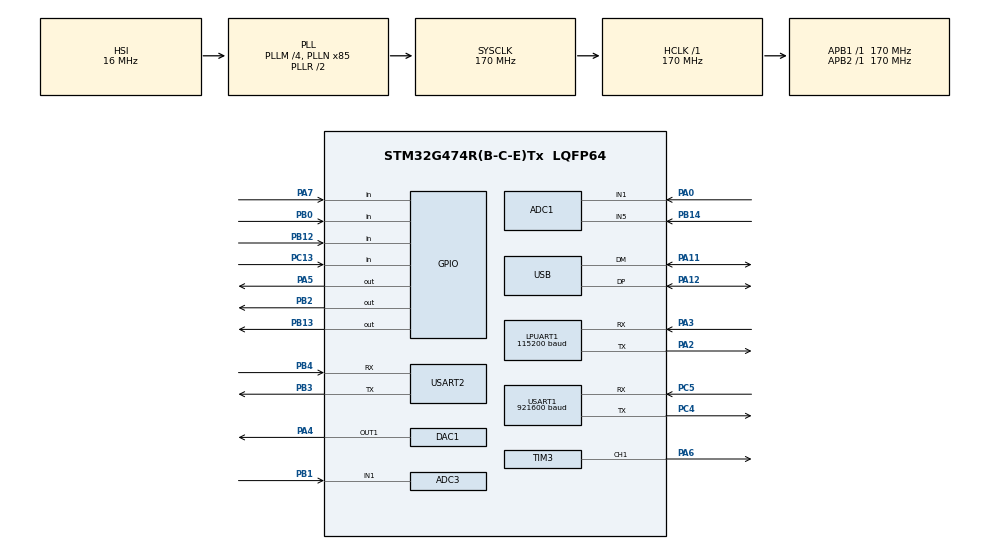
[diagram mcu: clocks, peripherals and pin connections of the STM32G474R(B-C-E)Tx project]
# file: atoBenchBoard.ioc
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ADC1.Channel-0\#ChannelRegularConversion=ADC_CHANNEL_1
ADC1.Channel-1\#ChannelRegularConversion=ADC_CHANNEL_5
ADC1.EOCSelection=ADC_EOC_SEQ_CONV
ADC1.ExternalTrigConv=ADC_EXTERNALTRIG_T7_TRGO
ADC1.NbrOfConversion=2
ADC1.NbrOfConversionFlag=1
ADC1.OffsetNumber-0\#ChannelRegularConversion=ADC_OFFSET_NONE
ADC1.OffsetNumber-1\#ChannelRegularConversion=ADC_OFFSET_NONE
ADC1.Rank-0\#ChannelRegularConversion=1
ADC1.Rank-1\#ChannelRegularConversion=2
ADC1.SamplingTime-0\#ChannelRegularConversion=ADC_SAMPLETIME_47CYCLES_5
ADC1.SamplingTime-1\#ChannelRegularConversion=ADC_SAMPLETIME_47CYCLES_5
ADC1.master=1
ADC3.Channel-0\#ChannelRegularConversion=ADC_CHANNEL_1
ADC3.NbrOfConversionFlag=1
ADC3.OffsetNumber-0\#ChannelRegularConversion=ADC_OFFSET_NONE
ADC3.Rank-0\#ChannelRegularConversion=1
ADC3.SamplingTime-0\#ChannelRegularConversion=ADC_SAMPLETIME_2CYCLES_5
ADC3.master=1
DAC1.DAC_Trigger_OUT1-DAC_OUT1=DAC_TRIGGER_T7_TRGO
Dma.ADC1.2.Direction=DMA_PERIPH_TO_MEMORY
Dma.ADC1.2.EventEnable=DISABLE
Dma.ADC1.2.Instance=DMA1_Channel3
Dma.ADC1.2.MemDataAlignment=DMA_MDATAALIGN_HALFWORD
Dma.ADC1.2.MemInc=DMA_MINC_ENABLE
Dma.ADC1.2.Mode=DMA_NORMAL
Dma.ADC1.2.PeriphDataAlignment=DMA_PDATAALIGN_HALFWORD
Dma.ADC1.2.PeriphInc=DMA_PINC_DISABLE
Dma.ADC1.2.Polarity=HAL_DMAMUX_REQ_GEN_RISING
Dma.ADC1.2.Priority=DMA_PRIORITY_LOW
Dma.ADC1.2.RequestNumber=1
Dma.ADC1.2.SignalID=NONE
Dma.ADC1.2.SyncEnable=DISABLE
Dma.ADC1.2.SyncPolarity=HAL_DMAMUX_SYNC_NO_EVENT
Dma.ADC1.2.SyncRequestNumber=1
Dma.ADC1.2.SyncSignalID=NONE
Dma.DAC1_CH1.3.Direction=DMA_MEMORY_TO_PERIPH
Dma.DAC1_CH1.3.EventEnable=DISABLE
Dma.DAC1_CH1.3.Instance=DMA1_Channel4
Dma.DAC1_CH1.3.MemDataAlignment=DMA_MDATAALIGN_HALFWORD
Dma.DAC1_CH1.3.MemInc=DMA_MINC_ENABLE
Dma.DAC1_CH1.3.Mode=DMA_CIRCULAR
Dma.DAC1_CH1.3.PeriphDataAlignment=DMA_PDATAALIGN_WORD
Dma.DAC1_CH1.3.PeriphInc=DMA_PINC_DISABLE
Dma.DAC1_CH1.3.Polarity=HAL_DMAMUX_REQ_GEN_RISING
Dma.DAC1_CH1.3.Priority=DMA_PRIORITY_LOW
Dma.DAC1_CH1.3.RequestNumber=1
Dma.DAC1_CH1.3.SignalID=NONE
Dma.DAC1_CH1.3.SyncEnable=DISABLE
Dma.DAC1_CH1.3.SyncPolarity=HAL_DMAMUX_SYNC_NO_EVENT
Dma.DAC1_CH1.3.SyncRequestNumber=1
Dma.DAC1_CH1.3.SyncSignalID=NONE
Dma.Request0=USART1_RX
Dma.Request1=USART1_TX
Dma.Request2=ADC1
Dma.Request3=DAC1_CH1
Dma.USART1_RX.0.Direction=DMA_PERIPH_TO_MEMORY
Dma.USART1_RX.0.EventEnable=DISABLE
Dma.USART1_RX.0.Instance=DMA1_Channel1
Dma.USART1_RX.0.MemDataAlignment=DMA_MDATAALIGN_BYTE
Dma.USART1_RX.0.MemInc=DMA_MINC_ENABLE
Dma.USART1_RX.0.Mode=DMA_CIRCULAR
Dma.USART1_RX.0.PeriphDataAlignment=DMA_PDATAALIGN_BYTE
Dma.USART1_RX.0.PeriphInc=DMA_PINC_DISABLE
Dma.USART1_RX.0.Polarity=HAL_DMAMUX_REQ_GEN_RISING
Dma.USART1_RX.0.Priority=DMA_PRIORITY_LOW
Dma.USART1_RX.0.RequestNumber=1
Dma.USART1_RX.0.SignalID=NONE
Dma.USART1_RX.0.SyncEnable=DISABLE
Dma.USART1_RX.0.SyncPolarity=HAL_DMAMUX_SYNC_NO_EVENT
Dma.USART1_RX.0.SyncRequestNumber=1
Dma.USART1_RX.0.SyncSignalID=NONE
Dma.USART1_TX.1.Direction=DMA_MEMORY_TO_PERIPH
Dma.USART1_TX.1.EventEnable=DISABLE
Dma.USART1_TX.1.Instance=DMA1_Channel2
Dma.USART1_TX.1.MemDataAlignment=DMA_MDATAALIGN_BYTE
Dma.USART1_TX.1.MemInc=DMA_MINC_ENABLE
Dma.USART1_TX.1.Mode=DMA_NORMAL
Dma.USART1_TX.1.PeriphDataAlignment=DMA_PDATAALIGN_BYTE
Dma.USART1_TX.1.PeriphInc=DMA_PINC_DISABLE
Dma.USART1_TX.1.Polarity=HAL_DMAMUX_REQ_GEN_RISING
Dma.USART1_TX.1.Priority=DMA_PRIORITY_LOW
Dma.USART1_TX.1.RequestNumber=1
Dma.USART1_TX.1.SignalID=NONE
Dma.USART1_TX.1.SyncEnable=DISABLE
Dma.USART1_TX.1.SyncPolarity=HAL_DMAMUX_SYNC_NO_EVENT
Dma.USART1_TX.1.SyncRequestNumber=1
Dma.USART1_TX.1.SyncSignalID=NONE
FREERTOS.Tasks01=defaultTask,0,128,StartDefaultTask,Default,NULL,Dynamic,NULL,NULL
FREERTOS.configCHECK_FOR_STACK_OVERFLOW=2
FREERTOS.configENABLE_FPU=1
FREERTOS.configTOTAL_HEAP_SIZE=16384
FREERTOS.configUSE_MALLOC_FAILED_HOOK=1
FREERTOS.configUSE_NEWLIB_REENTRANT=1
FREERTOS.configUSE_STATS_FORMATTING_FUNCTIONS=1
FREERTOS.configUSE_TRACE_FACILITY=1
LPUART1.BaudRate=115200
Mcu.Family=STM32G4
Mcu.Name=STM32G474R(B-C-E)Tx
Mcu.Package=LQFP64
NUCLEO-G474RE.BUTTON=2
NUCLEO-G474RE.LD2=false
NUCLEO-G474RE.VCP=false
NVIC.ADC1_2_IRQn=true\:5\:0\:false\:false\:true\:true\:true\:true\:true
NVIC.DMA1_Channel1_IRQn=true\:5\:0\:false\:false\:true\:true\:false\:true\:true
NVIC.DMA1_Channel2_IRQn=true\:5\:0\:false\:false\:true\:true\:false\:true\:true
NVIC.DMA1_Channel3_IRQn=true\:5\:0\:false\:false\:true\:true\:false\:true\:true
NVIC.DMA1_Channel4_IRQn=true\:5\:0\:false\:false\:true\:true\:false\:true\:true
NVIC.PriorityGroup=NVIC_PRIORITYGROUP_4
NVIC.TIM6_DAC_IRQn=true\:5\:0\:false\:false\:true\:false\:false\:true\:true
NVIC.TimeBase=TIM6_DAC_IRQn
NVIC.TimeBaseIP=TIM6
NVIC.USART1_IRQn=true\:5\:0\:false\:false\:true\:true\:true\:true\:true
NVIC.USB_LP_IRQn=true\:5\:0\:false\:false\:false\:true\:true\:true\:false
PA0.Mode=IN1-Single-Ended
PA0.Signal=ADC1_IN1
PA11.Mode=Device
PA11.Signal=USB_DM
PA12.Mode=Device
PA12.Signal=USB_DP
PA13.Mode=Serial_Wire
PA13.Signal=SYS_JTMS-SWDIO
PA14.Mode=Serial_Wire
PA14.Signal=SYS_JTCK-SWCLK
PA2.GPIO_PuPd=GPIO_PULLUP
PA2.Mode=Asynchronous
PA2.Signal=LPUART1_TX
PA3.GPIO_PuPd=GPIO_PULLUP
PA3.Mode=Asynchronous
PA3.Signal=LPUART1_RX
PA4.Signal=COMP_DAC11_group
PA5.Signal=GPIO_Output
PA6.Signal=S_TIM3_CH1
PA7.GPIO_PuPd=GPIO_PULLUP
PA7.Signal=GPIO_Input
PB0.GPIO_PuPd=GPIO_PULLDOWN
PB0.Signal=GPIO_Input
PB1.Mode=IN1-Single-Ended
PB1.Signal=ADC3_IN1
PB12.GPIO_PuPd=GPIO_PULLUP
PB12.Signal=GPIO_Input
PB13.Signal=GPIO_Output
PB14.Mode=IN5-Single-Ended
PB14.Signal=ADC1_IN5
PB2.Signal=GPIO_Output
PB3.Mode=Asynchronous
PB3.Signal=USART2_TX
PB4.Mode=Asynchronous
PB4.Signal=USART2_RX
PC13.Signal=GPIO_Input
PC4.Mode=Asynchronous
PC4.Signal=USART1_TX
PC5.Mode=Asynchronous
PC5.Signal=USART1_RX
ProjectManager.HeapSize=0x200
ProjectManager.StackSize=0x400
ProjectManager.TargetToolchain=CMake
RCC.ADC12Freq_Value=170000000
RCC.ADC345Freq_Value=170000000
RCC.AHBFreq_Value=170000000
RCC.APB1Freq_Value=170000000
RCC.APB1TimFreq_Value=170000000
RCC.APB2Freq_Value=170000000
RCC.APB2TimFreq_Value=170000000
RCC.CK48CLockSelection=RCC_USBCLKSOURCE_HSI48
RCC.CortexFreq_Value=170000000
RCC.EXTERNAL_CLOCK_VALUE=12288000
RCC.HCLKFreq_Value=170000000
RCC.HSE_VALUE=24000000
RCC.HSI48_VALUE=48000000
RCC.HSI_VALUE=16000000
RCC.LSE_VALUE=32768
RCC.PLLM=RCC_PLLM_DIV4
RCC.PLLN=85
RCC.SYSCLKFreq_VALUE=170000000
RCC.SYSCLKSource=RCC_SYSCLKSOURCE_PLLCLK
RCC.USBFreq_Value=48000000
RCC.VCOOutputFreq_Value=340000000
SH.COMP_DAC11_group.0=DAC1_OUT1,DAC_OUT1
SH.S_TIM3_CH1.0=TIM3_CH1,PWM Generation1 CH1
TIM3.AutoReloadPreload=TIM_AUTORELOAD_PRELOAD_ENABLE
TIM3.Channel-PWM\ Generation1\ CH1=TIM_CHANNEL_1
TIM3.PeriodNoDither=2272
TIM3.Prescaler=169
TIM3.PulseNoDither_1=1136
TIM7.TIM_MasterOutputTrigger=TIM_TRGO_UPDATE
USART1.BaudRate=921600
USART1.VirtualMode-Asynchronous=VM_ASYNC
USART2.VirtualMode-Asynchronous=VM_ASYNC
VP_FREERTOS_VS_CMSIS_V1.Mode=CMSIS_V1
VP_NUCLEO-G474RE_VS_BSP_COMMON.Mode=COMMON
VP_RCC_VS_USB.Mode=USB_FS
VP_SYS_VS_DBSignals.Mode=DisableDeadBatterySignals
VP_SYS_VS_tim6.Mode=TIM6
VP_TIM7_VS_ClockSourceINT.Mode=Enable_Timer
board=NUCLEO-G474RE

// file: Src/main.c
/* USER CODE BEGIN Header */
/**
 ******************************************************************************
 * @file           : main.c
 * @brief          : Main program body
 ******************************************************************************
 * @attention
 *
 * Copyright (c) 2026 STMicroelectronics.
 * All rights reserved.
 *
 * This software is licensed under terms that can be found in the LICENSE file
 * in the root directory of this software component.
 * If no LICENSE file comes with this software, it is provided AS-IS.
 *
 ******************************************************************************
 */
/* USER CODE END Header */
#include "main.h"
#include "cmsis_os.h"
#include "adc.h"
#include "dac.h"
#include "dma.h"
#include "usart.h"
#include "tim.h"
#include "usb.h"
#include "gpio.h"

/* USER CODE BEGIN Includes */
#include "stm32g4xx_nucleo.h"
#include <stdio.h>
/* USER CODE END Includes */

void SystemClock_Config(void);
void MX_FREERTOS_Init(void);

int main(void)
{

  /* MCU Configuration--------------------------------------------------------*/

  /* Reset of all peripherals, Initializes the Flash interface and the Systick. */
  HAL_Init();

  /* Configure the system clock */
  SystemClock_Config();

  /* Initialize all configured peripherals */
  MX_GPIO_Init();
  MX_DMA_Init();
  MX_USART1_UART_Init();
  MX_USART2_UART_Init();
  MX_LPUART1_UART_Init();
  MX_ADC1_Init();
  MX_DAC1_Init();
  MX_TIM7_Init();
  MX_TIM3_Init();
  MX_ADC3_Init();
  MX_USB_PCD_Init();
  /* USER CODE BEGIN 2 */

  printf("main()\r\n");
  printf("Board Name : %s\r\n", BSP_GetBoardName());

  /* Hello LED */

  /* USER CODE END 2 */

  /* Call init function for freertos objects (in cmsis_os2.c) */
  MX_FREERTOS_Init();

  /* Initialize User push-button without interrupt mode. */
  BSP_PB_Init(BUTTON_USER, BUTTON_MODE_GPIO);

  /* Start scheduler */
  osKernelStart();

  /* We should never get here as control is now taken by the scheduler */

  /* Infinite loop */
  while (1) {

  }
}

void SystemClock_Config(void)
{
  RCC_OscInitTypeDef RCC_OscInitStruct = {0};
  RCC_ClkInitTypeDef RCC_ClkInitStruct = {0};
  RCC_CRSInitTypeDef pInit = {0};

  /** Configure the main internal regulator output voltage
  */
  HAL_PWREx_ControlVoltageScaling(PWR_REGULATOR_VOLTAGE_SCALE1_BOOST);

  /** Initializes the RCC Oscillators according to the specified parameters
  * in the RCC_OscInitTypeDef structure.
  */
  RCC_OscInitStruct.OscillatorType = RCC_OSCILLATORTYPE_HSI|RCC_OSCILLATORTYPE_HSI48;
  RCC_OscInitStruct.HSIState = RCC_HSI_ON;
  RCC_OscInitStruct.HSICalibrationValue = RCC_HSICALIBRATION_DEFAULT;
  RCC_OscInitStruct.HSI48State = RCC_HSI48_ON;
  RCC_OscInitStruct.PLL.PLLState = RCC_PLL_ON;
  RCC_OscInitStruct.PLL.PLLSource = RCC_PLLSOURCE_HSI;
  RCC_OscInitStruct.PLL.PLLM = RCC_PLLM_DIV4;
  RCC_OscInitStruct.PLL.PLLN = 85;
  RCC_OscInitStruct.PLL.PLLP = RCC_PLLP_DIV2;
  RCC_OscInitStruct.PLL.PLLQ = RCC_PLLQ_DIV2;
  RCC_OscInitStruct.PLL.PLLR = RCC_PLLR_DIV2;
  if (HAL_RCC_OscConfig(&RCC_OscInitStruct) != HAL_OK)
  {
    Error_Handler();
  }

  /** Initializes the CPU, AHB and APB buses clocks
  */
  RCC_ClkInitStruct.ClockType = RCC_CLOCKTYPE_HCLK|RCC_CLOCKTYPE_SYSCLK
                              |RCC_CLOCKTYPE_PCLK1|RCC_CLOCKTYPE_PCLK2;
  RCC_ClkInitStruct.SYSCLKSource = RCC_SYSCLKSOURCE_PLLCLK;
  RCC_ClkInitStruct.AHBCLKDivider = RCC_SYSCLK_DIV1;
  RCC_ClkInitStruct.APB1CLKDivider = RCC_HCLK_DIV1;
  RCC_ClkInitStruct.APB2CLKDivider = RCC_HCLK_DIV1;

  if (HAL_RCC_ClockConfig(&RCC_ClkInitStruct, FLASH_LATENCY_4) != HAL_OK)
  {
    Error_Handler();
  }

  /** Enable the SYSCFG APB clock
  */
  __HAL_RCC_CRS_CLK_ENABLE();

  /** Configures CRS
  */
  pInit.Prescaler = RCC_CRS_SYNC_DIV1;
  pInit.Source = RCC_CRS_SYNC_SOURCE_USB;
  pInit.Polarity = RCC_CRS_SYNC_POLARITY_RISING;
  pInit.ReloadValue = __HAL_RCC_CRS_RELOADVALUE_CALCULATE(48000000,1000);
  pInit.ErrorLimitValue = 34;
  pInit.HSI48CalibrationValue = 32;

  HAL_RCCEx_CRSConfig(&pInit);
}

void HAL_TIM_PeriodElapsedCallback(TIM_HandleTypeDef *htim)
{
  if (htim->Instance == TIM6)
  {
    HAL_IncTick();
  }
}

void Error_Handler(void)
{
  __disable_irq();
  while (1) {
  }
}
#ifdef USE_FULL_ASSERT
/**
  * @brief  Reports the name of the source file and the source line number
  *         where the assert_param error has occurred.
  * @param  file: pointer to the source file name
  * @param  line: assert_param error line source number
  * @retval None
  */
void assert_failed(uint8_t *file, uint32_t line)
{
  /* USER CODE BEGIN 6 */
  /* User can add his own implementation to report the file name and line
     number, ex: printf("Wrong parameters value: file %s on line %d\r\n", file,
     line) */
  /* USER CODE END 6 */
}
#endif /* USE_FULL_ASSERT */

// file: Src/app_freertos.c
/* USER CODE BEGIN Header */
/**
 ******************************************************************************
 * File Name          : app_freertos.c
 * Description        : Code for freertos applications
 ******************************************************************************
 * @attention
 *
 * Copyright (c) 2026 STMicroelectronics.
 * All rights reserved.
 *
 * This software is licensed under terms that can be found in the LICENSE file
 * in the root directory of this software component.
 * If no LICENSE file comes with this software, it is provided AS-IS.
 *
 ******************************************************************************
 */
/* USER CODE END Header */

#include "FreeRTOS.h"
#include "cmsis_os.h"
#include "main.h"
#include "task.h"

/* USER CODE BEGIN Includes */
#include "ato_app.h"
/* USER CODE END Includes */

osThreadId defaultTaskHandle;

void StartDefaultTask(void const *argument);

void MX_FREERTOS_Init(void); /* (MISRA C 2004 rule 8.1) */

/* Hook prototypes */
void vApplicationStackOverflowHook(xTaskHandle xTask, signed char *pcTaskName);
void vApplicationMallocFailedHook(void);

void MX_FREERTOS_Init(void) {

  /* Create the thread(s) */
  /* definition and creation of defaultTask */
  osThreadDef(defaultTask, StartDefaultTask, osPriorityNormal, 0, 128);
  defaultTaskHandle = osThreadCreate(osThread(defaultTask), NULL);

  /* USER CODE BEGIN RTOS_THREADS */
  ato_app_start();

  /* USER CODE END RTOS_THREADS */
}

void StartDefaultTask(void const *argument) {
  for (;;) {
    osDelay(1);
  }
}
